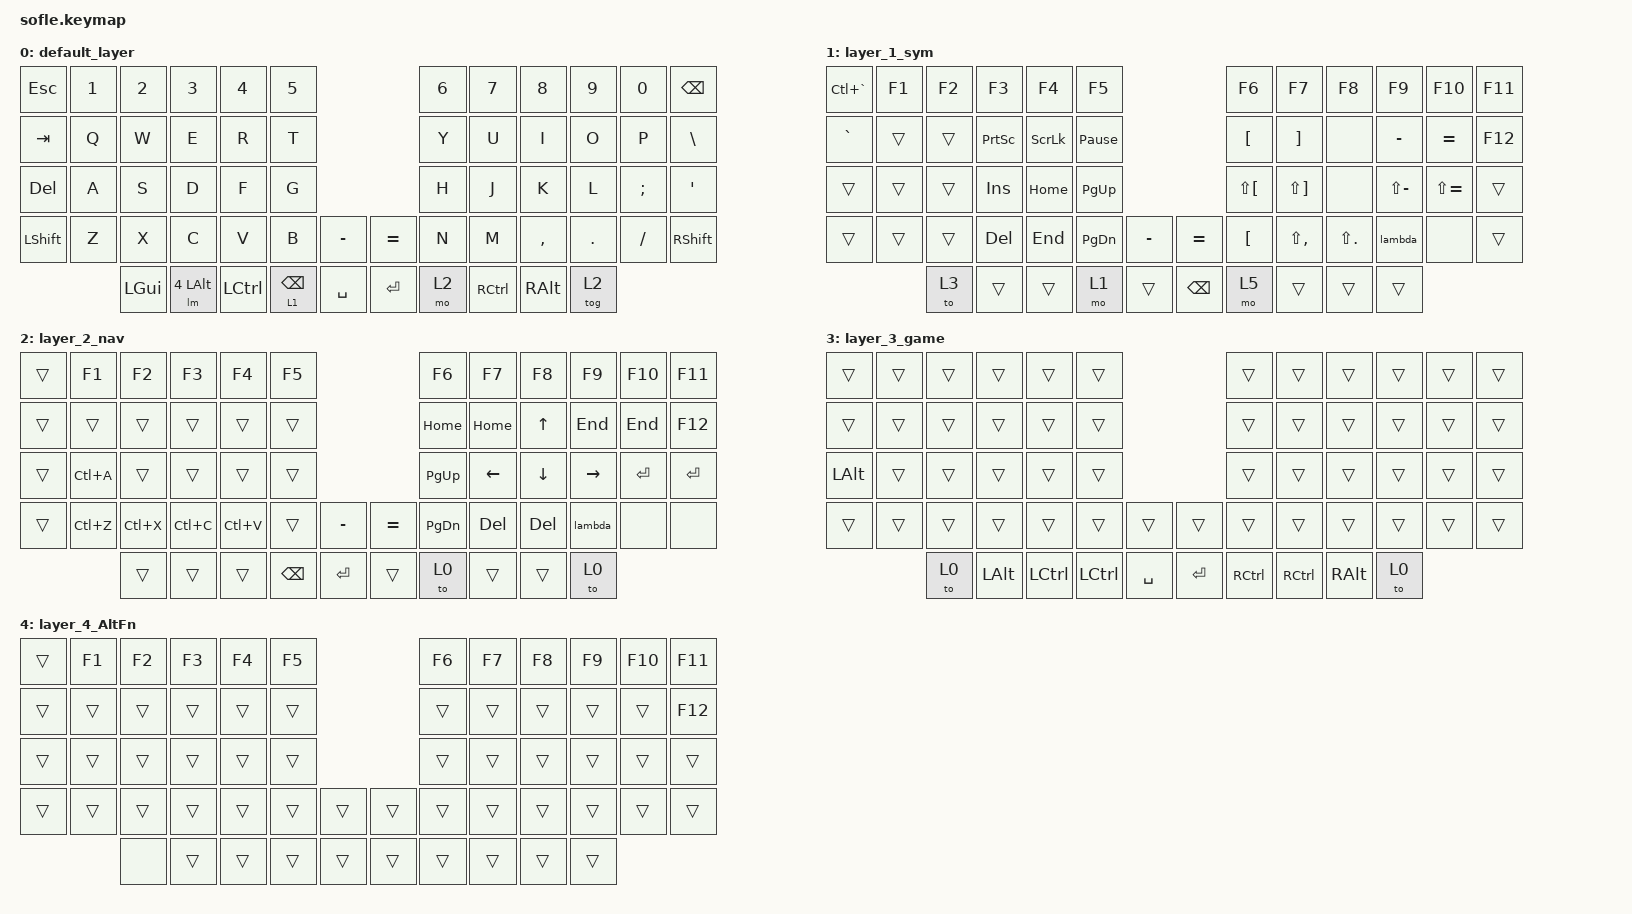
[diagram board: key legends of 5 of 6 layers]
/*
 * Copyright (c) 2020 The ZMK Contributors
 *
 * SPDX-License-Identifier: MIT
 */

#include <behaviors.dtsi>
#include <dt-bindings/zmk/keys.h>
#include <dt-bindings/zmk/bt.h>
#include <dt-bindings/zmk/rgb.h>

#define BASE 0
#define LOWER 1
#define RAISE 2
#define ADJUST 3

#include <dt-bindings/zmk/outputs.h>

/ {
    macros {
        lambda: lambda {
            label = "ZM_lambda";
            compatible = "zmk,behavior-macro";
			#binding-cells = <0>;
            wait-ms = <10>;
            bindings
                = <&macro_tap_time 10>
				, <&kp EQUAL>
                , <&kp LS(GREATER_THAN)>
                ;
        };
    };
};

/ {
	macros {
		lm: lm {
		    compatible = "zmk,behavior-macro-two-param";
		    wait-ms = <0>;
		    tap-ms = <0>;
		    #binding-cells = <2>;
		    bindings
		        = <&macro_param_1to1>
		        , <&macro_press &mo MACRO_PLACEHOLDER>
		        , <&macro_param_2to1>
		        , <&macro_press &kp MACRO_PLACEHOLDER>
		        , <&macro_pause_for_release>
		        , <&macro_param_2to1>
		        , <&macro_release &kp MACRO_PLACEHOLDER>
		        , <&macro_param_1to1>
		        , <&macro_release &mo MACRO_PLACEHOLDER>
		        ;
		};
	};

	behaviors {
		ltc: behavior_layer_tap {
			compatible = "zmk,behavior-hold-tap";
			label = "LAYER_TAP";
			#binding-cells = <2>;
			flavor = "tap-preferred";
			tapping-term-ms = <0>;
			bindings = <&mo>, <&kp>;
			retro-tap;
		};
	};


	behaviors {
		lth: behavior_layer_tap {
			compatible = "zmk,behavior-hold-tap";
			label = "LAYER_TAP";
			#binding-cells = <2>;
			flavor = "hold-preferred";
			tapping-term-ms = <50>;
			bindings = <&mo>, <&kp>;
			//retro-tap;
		};
	};

    keymap {
        compatible = "zmk,keymap";

// ------------------------------------------------------------------------------------------------------------
// |   `   |  1  |  2  |  3   |  4   |  5   |                   |  6   |  7    |  8    |  9   |   0   |       |
// |  ESC  |  Q  |  W  |  E   |  R   |  T   |                   |  Y   |  U    |  I    |  O   |   P   | BKSPC |
// |  TAB  |  A  |  S  |  D   |  F   |  G   |                   |  H   |  J    |  K    |  L   |   ;   |   '   |
// | SHIFT |  Z  |  X  |  C   |  V   |  B   |  MUTE  |  |       |  N   |  M    |  ,    |  .   |   /   | SHIFT |
//               | GUI | ALT  | CTRL | LOWER|  ENTER |  | SPACE | RAISE| CTRL  | ALT   | GUI  |

default_layer { bindings = <

&kp ESC			&kp N1			&kp N2			&kp N3			&kp N4			&kp N5											&kp N6			&kp N7			&kp N8			&kp N9			&kp N0			&kp BACKSPACE
&kp TAB			&kp Q			&kp W			&kp E			&kp R			&kp T											&kp Y			&kp U			&kp I			&kp O			&kp P			&kp BACKSLASH
&kp	DEL			&kp A			&kp S			&kp D			&kp F			&kp G											&kp H			&kp J			&kp K			&kp L			&kp SEMI		&kp SINGLE_QUOTE
&kp LSHFT		&kp Z			&kp X			&kp C			&kp V			&kp B				&kp MINUS	&kp EQUAL		&kp N			&kp M			&kp COMMA		&kp DOT			&kp SLASH		&kp RSHFT
								&kp LGUI		&lm 4 LALT		&kp LCTRL		&ltc 1 BACKSPACE 	&kp SPACE	&kp RET			&mo 2			&kp RCTRL		&kp RALT		&tog 2
>;};

layer_1_sym { bindings = <

&kp LC(GRAVE)	&kp F1			&kp F2			&kp F3			&kp F4			&kp F5											&kp F6			&kp F7			&kp F8			&kp F9			&kp F10			&kp F11
&kp GRAVE		&trans 			&trans			&kp PRINTSCREEN	&kp SCROLLLOCK	&kp PAUSE_BREAK									&kp LBKT		&kp RBKT		&none			&kp MINUS		&kp EQUAL		&kp F12
&trans			&trans			&trans			&kp INS			&kp HOME		&kp PG_UP										&kp LS(LBKT)	&kp LS(RBKT)	&none			&kp LS(MINUS)	&kp LS(EQUAL)	&trans
&trans			&trans			&trans			&kp DEL			&kp END			&kp PG_DN			&kp MINUS	&kp EQUAL		&kp LBKT		&kp LS(COMMA)	&kp LS(DOT)		&lambda			&none			&trans
								&to 3			&trans			&trans			&mo 1				&trans		&kp BACKSPACE	&mo 5			&trans			&trans			&trans
>;};

layer_2_nav { bindings = <

&trans			&kp F1			&kp F2			&kp F3			&kp F4			&kp F5											&kp F6			&kp F7			&kp F8			&kp F9			&kp F10			&kp F11
&trans			&trans			&trans			&trans			&trans			&trans											&kp HOME		&kp HOME		&kp UP			&kp END	&kp END			&kp F12
&trans			&kp LC(A)		&trans			&trans			&trans			&trans											&kp PG_UP		&kp LEFT		&kp DOWN		&kp RIGHT		&kp RET			&kp RET  
&trans			&kp LC(Z)		&kp LC(X)		&kp LC(C)		&kp LC(V)		&trans				&kp MINUS	&kp EQUAL		&kp PG_DN		&kp DEL			&kp DEL			&lambda			&none			&none
								&trans			&trans			&trans			&kp BACKSPACE		&kp RET		&trans			&to 0 			&trans			&trans			&to 0
>;};

layer_3_game { bindings = <

&trans			&trans			&trans			&trans			&trans			&trans          								&trans			&trans			&trans			&trans			&trans			&trans
&trans			&trans			&trans			&trans			&trans			&trans          								&trans			&trans			&trans			&trans			&trans			&trans
&kp LALT		&trans			&trans			&trans			&trans			&trans											&trans			&trans			&trans			&trans			&trans			&trans
&trans			&trans			&trans			&trans			&trans			&trans				&trans		&trans			&trans			&trans			&trans			&trans			&trans			&trans
								&to 0			&kp LALT		&kp LCTRL		&kp LCTRL			&kp SPACE	&kp RET			&kp RCTRL		&kp RCTRL		&kp RALT		&to 0
>;};

layer_4_AltFn { bindings = <
&trans			&kp F1			&kp F2			&kp F3			&kp F4			&kp F5											&kp F6			&kp F7			&kp F8			&kp F9			&kp F10			&kp F11
&trans			&trans			&trans			&trans			&trans			&trans          								&trans			&trans			&trans			&trans			&trans			&kp F12
&trans			&trans			&trans			&trans			&trans			&trans											&trans			&trans			&trans			&trans			&trans			&trans
&trans			&trans			&trans			&trans			&trans			&trans				&trans		&trans			&trans			&trans			&trans			&trans			&trans			&trans
								&none			&trans			&trans			&trans				&trans		&trans			&trans			&trans			&trans			&trans				
>; };


layer_5_system { bindings = <
// -----------------------------------------------------------------------------------------
// | RST | BLDR |     |     |     |     |     |   |     |     |     |     |     | BLDR | RST |
//       | BTCLR| BT0 | BT1 | BT2 | BT3 | BT4 |   | BT4 | BT3 | BT2 | BT1 | BT0 | BTCLR|
//       |      |     |     |     |     |     |   |     |     |     |     |     |      |
//                          |     |     |     |   |     |     |     |

&bt BT_CLR   	&bt BT_SEL 0 	&bt BT_SEL 1 	&bt BT_SEL 2 	&bt BT_SEL 3 	&bt BT_SEL 4       								&bt BT_SEL 4 	&bt BT_SEL 3 	&bt BT_SEL 2 	&bt BT_SEL 1 	&bt BT_SEL 0  	&bt BT_CLR
&none 			&bootloader		&none			&none			&none			&none          									&none			&out OUT_TOG	&none			&none			&bootloader 	&none
&none			&none			&none			&none			&none			&none											&none			&none			&none			&none			&none			&none
&none			&none			&none			&none			&none			&none											&none			&none			&none			&none			&none			&none
&none			&none			&none			&none			&none			&out OUT_TOG	&out OUT_USB	&out OUT_BLE	&out OUT_TOG	&none			&none			&none			&none			&none
								&trans			&trans			&trans			&mo 5			&trans			&mo 5			&trans			&trans			&trans			&trans		
>; }; 

    };
};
